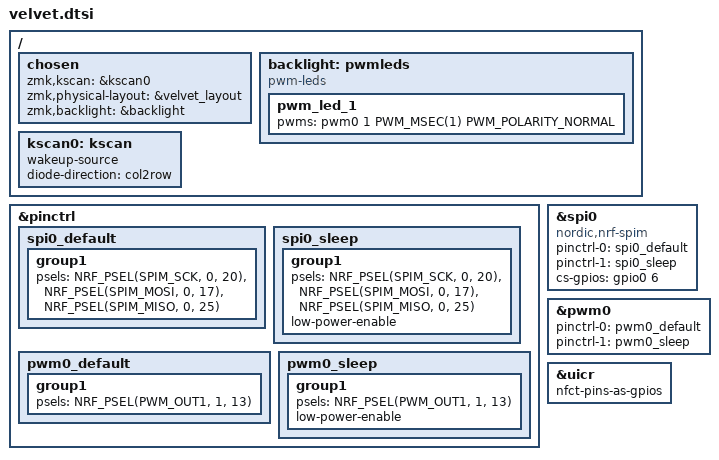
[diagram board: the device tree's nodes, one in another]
#include <dt-bindings/zmk/matrix_transform.h>
#include "velvet-layouts.dtsi"
#include <dt-bindings/led/led.h>

/ {
	chosen {
		zmk,kscan = &kscan0;
		zmk,physical-layout = &velvet_layout;
		zmk,backlight = &backlight;
	};

	backlight: pwmleds {
		compatible = "pwm-leds";
		pwm_led_1: pwm_led_1 {
			pwms = <&pwm0 1 PWM_MSEC(1) PWM_POLARITY_NORMAL>;
		};
	};
#include "velvet-numpad-transform.dtsi"

    kscan0: kscan {
        wakeup-source;
        diode-direction = "col2row";
    };

};


&pinctrl {

    spi0_default: spi0_default {
        group1 {
            psels = <NRF_PSEL(SPIM_SCK, 0, 20)>,
                <NRF_PSEL(SPIM_MOSI, 0, 17)>,
                <NRF_PSEL(SPIM_MISO, 0, 25)>;
        };
    };

    spi0_sleep: spi0_sleep {
        group1 {
            psels = <NRF_PSEL(SPIM_SCK, 0, 20)>,
                <NRF_PSEL(SPIM_MOSI, 0, 17)>,
                <NRF_PSEL(SPIM_MISO, 0, 25)>;
            low-power-enable;
        };
    };

	pwm0_default: pwm0_default {
        group1 {
            psels = <NRF_PSEL(PWM_OUT1, 1, 13)>; // LED 1
           
        };
    };
    pwm0_sleep: pwm0_sleep {
        group1 {
            psels = <NRF_PSEL(PWM_OUT1, 1, 13)>; // LED 1
            low-power-enable;
        };
    };
};

nice_view_spi: &spi0 {
    compatible = "nordic,nrf-spim";
    pinctrl-0 = <&spi0_default>;
    pinctrl-1 = <&spi0_sleep>;
    pinctrl-names = "default", "sleep";
    cs-gpios = <&gpio0 6 GPIO_ACTIVE_HIGH>;
};

&pwm0 {
    status = "okay";
    pinctrl-0 = <&pwm0_default>;
    pinctrl-1 = <&pwm0_sleep>;
    pinctrl-names = "default", "sleep";
};

// ZMK 4.1: NFC pins as GPIO moved from CONFIG_NFCT_PINS_AS_GPIOS=y to devicetree.
// Required when routing the nRF52840 NFC pins (P0.09/P0.10) to other uses
// such as SPI for the OLED (nice_view) on this firmware.
&uicr {
    nfct-pins-as-gpios;
};
